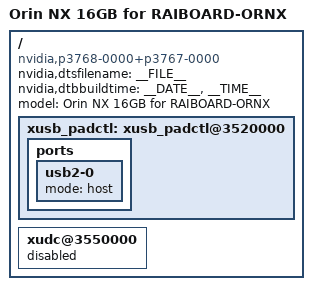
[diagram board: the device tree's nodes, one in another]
/*
 * Top level DTS file for CVM:P3767-0000 and CVB:RAIBOARD-ORNX.
 *
 * Copyright (c) 2021-2022, NVIDIA CORPORATION.  All rights reserved.
 *
 * This program is free software; you can redistribute it and/or modify
 * it under the terms of the GNU General Public License as published by
 * the Free Software Foundation; version 2 of the License.
 *
 * This program is distributed in the hope that it will be useful, but WITHOUT
 * ANY WARRANTY; without even the implied warranty of MERCHANTABILITY or
 * FITNESS FOR A PARTICULAR PURPOSE.  See the GNU General Public License for
 * more details.
 */

/dts-v1/;

#include "tegra234-p3767-0000-p3768-0000-a0-raiboard-ornx-base.dts"

/ {
	nvidia,dtsfilename = __FILE__;
	nvidia,dtbbuildtime = __DATE__, __TIME__;
	compatible = "nvidia,p3768-0000+p3767-0000", "nvidia,tegra234", "nvidia,tegra23x";
	model = "Orin NX 16GB for RAIBOARD-ORNX";

	xusb_padctl: xusb_padctl@3520000 {
		ports {
			usb2-0 {/* Goes to recovery port */
				mode = "host";
				/delete-property/ usb-role-switch;
				/delete-node/ connector;
			};
		};
	};

	xudc@3550000 {
		status = "disabled";
	};
};
